# cslr_ddr_001 register map
Vendor: Texas Instruments
Peripheral module from a debugger description file.
Registers are 32-bit, access per field, reset 0x0 unless marked. A register's access mark holds for its fields unless they carry their own. Offsets are as the file gives them; lines under a group give offsets from that group; [hi:lo] are bit positions; {n}, {i} and the like mark numbered series; 'fields as' and 'values as' point back to an identical list; <NAME> marks a mode.

## DDR — External Memory Interface - DDR
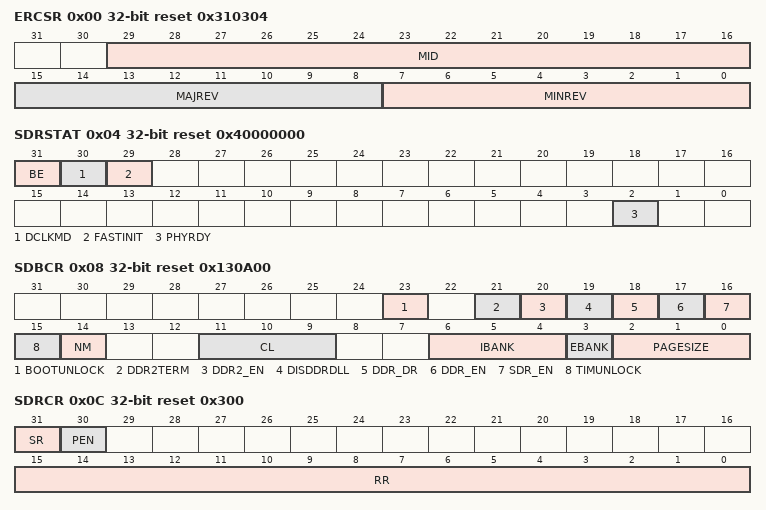
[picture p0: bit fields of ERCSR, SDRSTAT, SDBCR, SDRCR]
0x00 ERCSR ro reset 0x310304 — EMIF Revision Code and Status register
  [29:16] MID — EMIF Module ID
  [15:8] MAJREV — EMIF Major Revision Number
  [7:0] MINREV — EMIF Minor Revision Number
0x04 SDRSTAT ro reset 0x40000000 — SDRAM Status Register
  [31] BE — Big Endian Specifies whether the EMIF is in big or little endian mode
  [30] DCLKMD — Dual Clock Mode Specifies whether the vclk and mclk inputs are asynchronous
  [29] FASTINIT — Fast Init Specifies whether EMIF fast initialization mode has been enabled
  [2] PHYRDY — DDR PHY Ready Specifies whether the DDR PHY is ready for normal operation
0x08 SDBCR reset 0x130A00 (reset mask 0xFF9BFF8F) — SDRAM Bank Configuration Register
  [23] BOOTUNLOCK rw — Boot Unlock Set to 1 to change values of register fields that are affected by this bit.
  [21] DDR2TERM rw — DDR2 Termination resistor value. Set to 1 for 150 ohm, 0 for 75 ohm
    0=TERM75 (Termination resistor = 75 ohm); 1=TERM150 (Termination resistor = 150 ohm)
  [20] DDR2_EN rw — DDR2 Enable Specifies whether the DDR2 mode has been enabled
  [19] DISDDRDLL rw — Disable DLL select for DDR1 SDRAM Set to 1 to disable DLL inside DDR1 SDRAM
  [18] DDR_DR rw — DDR SDRAM drive strength.
    0=NORM (Normal drive strength); 1=WEAK (Weak drive strength)
  [17] DDR_EN rw — Double Rate Specifies whether the EMIF is set to operate at double or single data rate
  [16] SDR_EN rw — SDRAM Enable. Define whether the SDRAM mode of the EMIF is enabled.
  [15] TIMUNLOCK rw — Timing unlock.
    1=UNLOCKTIM (Allowed to change values affected by this field)
  [14] NM rw — SDRAM Data Bus Width Set to 1 when the system bus width to memory bus width is 2:1 for SDR SDRAM and 4:1 for DDR SDRAM A write to this field will cause the EMIF to start the SDRAM initialization sequence
  [11:9] CL rw — CAS Latency A write to this field will cause the EMIF to start the SDRAM initialization sequence
    {v}=CASLAT{v} (CAS Latency of {v}) (v=2..5)
  [6:4] IBANK rw — Internal SDRAM Bank Setup Defines the number of banks inside the SDRAM connected
    0=SD1BANK (1 Bank SDRAM devices); 1=SD2BANK (2 Bank SDRAM devices); 2=SD4BANK (4 Bank SDRAM devices); 3=SD8BANK (8 Bank SDRAM devices)
  [3] EBANK rw — External SDRAM Bank Setup Defines whether the SDRAM bank accesses will use 1 or 2 chip select lines. A write to this field will cause the EMIF to start the SDRAM initialization sequence
    0=CS0 (CS0 is used for SDRAM accesses); 1=CS0_CS1 (CS0 and CS1 are used for SDRAM accesses)
  [2:0] PAGESIZE rw — Page Size Defines the internal page size of the connected SDRAM devices
    0=P256 (256-word pages requiring A[7:0] address pins); 1=P512 (512-word pages requiring A[8:0] address pins); 2=P1024 (1024-word pages requiring A[9:0] address pins); 3=P2048 (2048-word pages requiring A[10:0] address pins)
0x0C SDRCR reset 0x300 — SDRAM Refresh Control Register
  [31] SR rw — Self Refresh Writing a 1 to this bit will cause connected SDRAM devices to be placed into Self Refresh power-down mode and the EMIF to enter the Self-Refresh state
    1=SELFREF (Enter self refresh mode)
  [30] PEN rw — Error Detection 0: Disable error detection 1: Enable error detection
    0=DISABLE (Disable error detection); 1=ENABLE (Enable error detection)
  [15:0] RR rw — Refresh Rate Defines the rate at which EMIF refreshes the connected SDRAM devices. The refresh rate is the number of clock cycles required to cause a refresh interval for the appropriate SDRAM used SDRAM refresh rate = EMIF rate/ refresh rate where EMIF rate is equal to mclk rate Writing a value and#60; 0x0010 to this field will cause it to be loaded with the refresh_def_value
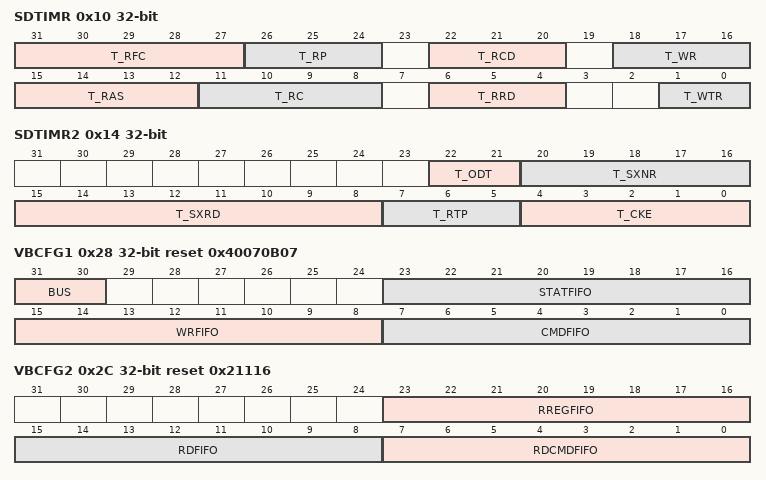
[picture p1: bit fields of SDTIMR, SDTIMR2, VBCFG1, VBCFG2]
0x10 SDTIMR — SDRAM Timing Register
  [31:27] T_RFC rw — Specifies Trfc value of the SDRAM is minimum number of EMIF clock cycles from Refresh (REFR) or Load Mode (MRS) to Refresh (REFR) or Activate (ACTV) command, minus one TRFC = (Trfc / SDCLK) - 1
  [26:24] T_RP rw — Specifies Trp value of the SDRAM is minimum number of EMIF cycles from Pre-charge to Active (ACTV) or Refresh (REFR/), minus one TRP = (Trp / SDCLK) - 1
  [22:20] T_RCD rw — Specifies Trcd value of the SDRAM is minimum number of EMIF cycles from Active (ACTV) to read (READ) or write (WRITE) command, minus one TRCD = (Trcd / SDCLK) - 1
  [18:16] T_WR rw — Specifies Twr value of the SDRAM is minimum number of EMIF cycles from last write transfer to Precharge command, minus one TWR = (Twr / SDCLK) - 1
  [15:12] T_RAS rw — Specifies Tras value of the SDRAM in EMIF clock cycles from Activate (ACT) to Precharge command, minus one TRAS = (Tras / SDCLK) - 1
  [11:8] T_RC rw — Specifies Trc value of the SDRAM is minimum number of EMIF clock cycles from Activate (ACT) to Activate (ACT) command, minus one TRC = (Trc / SDCLK) - 1
  [6:4] T_RRD rw — Specifies Trrd value of the SDRAM is minimum number of EMIF clock cycles from Activate (ACT) to Activate (ACT) command for a different bank, minus one TRRD = (Trrd / SDCLK) - 1
  [1:0] T_WTR rw — Specifies the minimum number of EMIF clock cycles from the last DDR write transfer to DDR read, minus one
0x14 SDTIMR2 — SDRAM Timing Register 2
  [22:21] T_ODT rw — Specified the minimum number of EMIF cycles minus one from ODT enable to write data driven. This field must be equal to (CAS latency -tAOND-1)
  [20:16] T_SXNR rw — Specifies the minimum number of EMIF clock cycles minus one from self-fresh exit to any command (except READ).
  [15:8] T_SXRD rw — Specifies the minimum number of EMIF clock cycles minus one from self-fresh exit to READ command.
  [7:5] T_RTP rw — Specifies the minimum number of EMIF clock cycles minus one from the last READ command to a Pre-Charge command.
  [4:0] T_CKE rw — Specifies the minimum number of EMIF clock cycles minus one for the pulse width of pad_mcke_o. This signal is used to put SDRAM devices in Self Refresh of Power Down.
0x20 VBPR reset 0xFF — VBUSM Burst Priority Register
  [7:0] PROC rw — Priority Raise Old Counter Specifies the number of memory bursts after which the EMIF raises the priority of old commands in the VBUSM Command FIFO
0x28 VBCFG1 ro reset 0x40070B07 — VBUSM Config Value 1 Register
  [31:30] BUS — VBUSM data bus width. 0:32-bit 1:64-bit 2 and 3: Reserved
  [23:16] STATFIFO — Write status FIFO depth.
  [15:8] WRFIFO — Write FIFO depth
  [7:0] CMDFIFO — Command FIFO depth.
0x2C VBCFG2 ro reset 0x21116 — VBUSM Config Value 2 Register
  [23:16] RREGFIFO — Async/Register read FIFO depth.
  [15:8] RDFIFO — SDRAM read FIFO depth.
  [7:0] RDCMDFIFO — Read command FIFO depth.
0x40 PERFC1R ro — Performance Counter 1 Register
  [31:0] COUNTER1 — 32-bit counter that can be configured as specified in the Performance Counter Config Register and Performance Counter Master Region Select Register This register is used for performance monitoring and is cleared only on reset
0x44 PERFC2R ro — Performance Counter 2 Register
  [31:0] COUNTER2 — 32-bit counter that can be configured as specified in the Performance Counter Config Register and Performance Counter Master Region Select Register This register is used for performance monitoring and is cleared only on reset
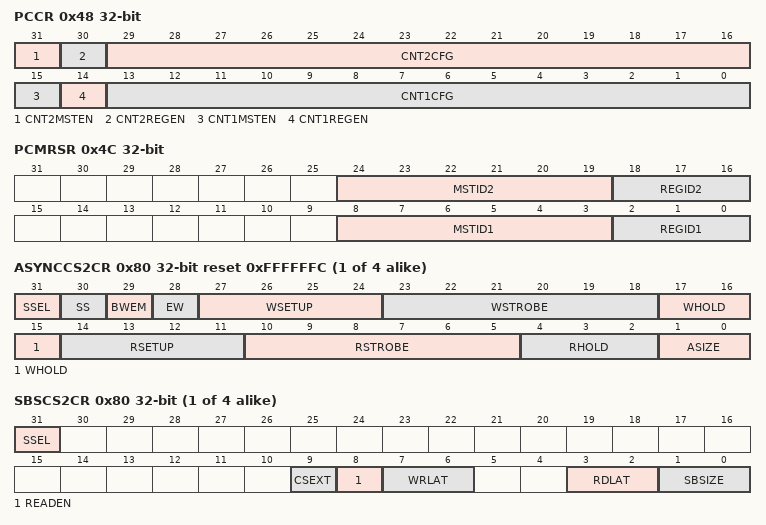
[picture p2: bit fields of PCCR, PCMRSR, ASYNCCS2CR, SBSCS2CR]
0x48 PCCR rw — Performance Counter Config Register
  [31] CNT2MSTEN — Master ID filter enable for Performance Counter 2
  [30] CNT2REGEN — Chip Select filter enable for Performance Counter 2
  [29:16] CNT2CFG — Filter configuration for Performance Counter 2
    0=SDACC (Total SDRAM accesses.); 1=SDACT (Total SDRAM activates.); 2=TOTRD (Total reads.); 3=TOTWR (Total writes.); 4=COMFULL (Number of cycles VBUSM command fifo is full.); 5=WRDATFULL (Number of cycles VBUSM write data fifo is full.); 6=RDDATFULL (Number of cycles VBUSM read data fifo is full.); 7=WRSTATFULL (Number of cycles VBUSM write status fifo is full.); 8=TOTPARERR (Total parity errors.); 9=PRIELEV (Number of priority elevations.); 10=PCHRGELEV (Number of pre-charge elevations.); 11=CMDPND (Number of cycles that a command was pending.)
  [15] CNT1MSTEN — Master ID filter enable for Performance Counter 1
  [14] CNT1REGEN — Chip Select filter enable for Performance Counter 1
  [13:0] CNT1CFG — Filter configuration for Performance Counter 1
    values as CNT2CFG
0x4C PCMRSR — Performance Counter Master Region Select Register
  [24:19] MSTID2 rw — Master ID for Performance Counter 2
  [18:16] REGID2 rw — Chip Select for Performance Counter 2
  [8:3] MSTID1 rw — Master ID for Performance Counter 1
  [2:0] REGID1 rw — Chip Select for Performance Counter 1
{0x78+4i} ASYNCCS{i}CR rw reset 0xFFFFFFC (i=2..5) — CS{i} Config Register for Asynchronous Memory Access (ssel = 0)
  [31] SSEL — Sync SBSRAM/Asynchronous memory select Set to 1 to configure chip select for synchronous SBSRAM memory. The other fields in this register define the bits in the bank when SSEL is set to 0 (asynchronous memory mode)
  [30] SS — Select Strobe mode Set to 1 if chip selects need to have write or read strobe timing
  [29] BWEM — Select WE Strobe mode When set to 1, the pado_mdqm_o_n[7/3:0] output pins will act as active low byte enables when accessing chip select N
  [28] EW — Extend Wait mode Set to 1 if extended asynchronous cycles are required based on padi_mwait_I
  [27:24] WSETUP — Wait Strobe Setup cycles Number of EMIF clock cycles from pado_ma_o, pado_mba_o, pad_d_o, pado_mdqm_o_n, and pado_mcs_o_n being set to pado_mwe_o_n asserted,minus one cycle.The reset value is 16 cycles
  [23:18] WSTROBE — Wait Strobe Duration cycles Number of EMIF clock cycles for which pado_mwe_o_n is held active, minus one cycle
  [17:15] WHOLD — Wait Strobe Hold cycles Number of EMIF clock cycles for which pado_ma_o, pado_mba_o, pad_d_o, pado_mdqm_o_n, and pado_mcs_o_n are held after pado_mwe_o_n has been deasserted, minus one cycle. The reset value is 8 cycles
  [14:11] RSETUP — Read Strobe Setup cycles Number of EMIF clock cycles from pado_ma_o, pado_mba_o, pado_mdqm_o_n, and pado_mcs_o_n being set to pado_moe_o_n asserted, minus one cycle. The reset value is 16 cycles
  [10:5] RSTROBE — Read Strobe Duration cycles Number of EMIF clock cycles for which pado_moe_o_n is held active, minus one cycle. The reset value is 64 cycles
  [4:2] RHOLD — Read Strobe Hold cycles Number of EMIF clock cycles for which pado_ma_o, pado_mba_o, pado_mdqm_o_n, and pado_mcs_o_n are held after pado_moe_o_n has been deasserted, minus one cycle. The reset value is 8 cycles
  [1:0] ASIZE — Asynchronous Bank Size Defines the width of the asynchronous bank's data bus, as follows
    0=DATA8 (8-bit data bus); 1=DATA16 (16-bit data bus); 2=DATA32 (32-bit data bus); 3=DATA64 (64-bit data bus)
{0x78+4i} SBSCS{i}CR (i=2..5) — CS{i} Config Register for Synchronous Burst SRAM Access (ssel = 1)
  [31] SSEL rw — Sync SBSRAM/Asynchronous memory select Set to 1 to configure chip select for synchronous SBSRAM memory. The other fields in this register define the bits in the bank when SSEL is set to 0 (asynchronous memory mode)
  [9] CSEXT rw — SBSRAM Bank Chip Select Extend. Defines the behavior of the pad_cs_o[n] pin associated with the SBSRAM bank, as follows 0: pad_cs_o[n] goes inactive after final command has been issued 1: pad_cs_o[n] goes active low when pado_moe_o_n goes active low and will stay active low until pado_moe_o_n is inactive.The pado_moe_o_n tining is controlled by the r_ltncy value for the SBSRAM bank. Used for synchronous FIFO reads
  [8] READEN rw — SBSRAM Bank Read Enable Mode Defines the behavior of the pado_mads_o_n signal when accessing the SBSRAM bank, as follows: 0: ADS mode.The pado_mads_o_n signal goes active low for reads and writes. A deselect command is issued by driving pado_mads_o_n active high after a command, if no new command is pending for the same bank. Used for SBSRAM and ZBT devices 1: Read enable mode. The pado_mads_o_n signal goes active low only for reads. No deselect command is issued. Used for FIFO interfaces
  [7:6] WRLAT rw — SBSRAM Bank Write Latency Defines the SBSRAM bank's write latency in clock cycles
    {v}={v} Cycle Write Latency (v=0..3)
  [3:2] RDLAT rw — SBSRAM Bank Read Latency Defines the SBSRAM bank's read latency in clock cycles, as follows:
    {v}={v} Cycle Read Latency (v=0..3)
  [1:0] SBSIZE rw — SBSRAM Bank Size Defines width of the SBSRAM bank's data bus
    values as ASYNCCS2CR.ASIZE
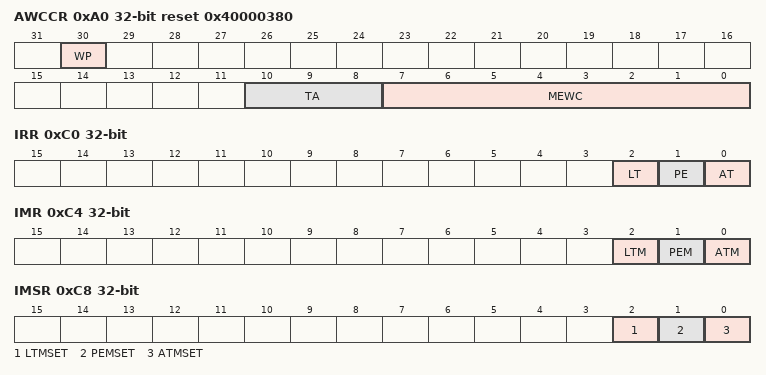
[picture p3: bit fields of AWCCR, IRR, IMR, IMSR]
0xA0 AWCCR reset 0x40000380 — Async Wait Cycle Config Register
  [30] WP rw — Wait Polarity Defines the polarity of the padpadi_mwait_i port, as follows: 0: Wait if padpadi_mwait_i port is low 1: Wait if padpadi_mwait_i port is high
  [10:8] TA rw — Turn Around cycles Number of EMIF clock cycles between the end of one asynchronous bank access and the start of another asynchronous bank access, minus one cycle. This delay is not incurred between a read followed by a read, or a write followed by a write to the same bank. The reset value is 4 cycles
  [7:0] MEWC rw — Maximum External Wait cycles The value in this field defines the number of 16 EMIF cycle periods the EMIF will wait for an extended asynchronous cycle before the cycle is terminated
0xC0 IRR — Interrupt Raw Register
  [2] LT rw — Line Trap Set to 1 by hardware to indicate illegal memory access type or invalid cache line size. Writing a 1 will clear this bit as well as the lt_masked bit in the Interrupt Masked register. Writing a 0 has no effect
  [1] PE rw — Parity Error Set to 1 by hardware to indicate a parity error during SDRAM access. Writing a 1 will clear this bit as well as the pe_masked bit in the Interrupt Masked register. Writing a 0 has no effect
  [0] AT rw — Asynchronous Timeout Set to 1 by hardware to indicate that during an extended asynchronous bank access cycle, the padi_mwait_i signal did not go inactive within the number of cycles defined by the max_ext_wait field in Async Wait Cycle Config register. Writing a 1 will clear this bit as well as the at_masked bit in the Interrupt Masked register. Writing a 0 has no effect
0xC4 IMR — Interrupt Masked Register
  [2] LTM rw — Masked Line Trap Set to 1 by hardware to indicate illegal memory access type or invalid cache line size. Writing a 1 will clear this bit as well as the lt bit in the Interrupt Raw register. Writing a 0 has no effect
  [1] PEM rw — Masked Parity Error Set to 1 by hardware to indicate a parity error during SDRAM access. Writing a 1 will clear this bit as well as the pe bit in the Interrupt Raw register. Writing a 0 has no effect
  [0] ATM rw — Masked Asynchronous Timeout Set to 1 by hardware to indicate that during an extended asynchronous bank access cycle, the padi_mwait_i signal did not go inactive within the number of cycles defined by the max_ext_wait field in Async Wait Cycle Config register. Writing a 1 will clear this bit as well as the at bit in the Interrupt Raw register. Writing a 0 has no effect
0xC8 IMSR — Interrupt Mask Set Register
  [2] LTMSET rw — Line Trap Mask Set Bit Writing a 1 in this bit field will enable the interrupt and set this bit in the Line Trap Mask bit field of the Interrupt Mask Clear Register. This bit is cleared by writing a 1 into this bit field
  [1] PEMSET rw — Parity Error Mask Set Bit Writing a 1 will enable the interrupt, and set this bit as well as the pe_mask_clr bit in the Interrupt Mask Clear register. Writing a 0 has no effect
  [0] ATMSET rw — Asynchronous Timeout Mask Set Bit Writing a 1 in this bit field will enable the interrupt and set this bit in the Asynchronous Timeout Mask Clear bit field of the Interrupt Mask Register. This bit is cleared by writing a 1 into this bit field
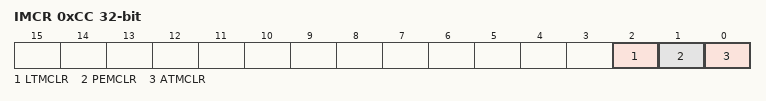
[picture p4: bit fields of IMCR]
0xCC IMCR — Interrupt Mask Clear Register
  [2] LTMCLR rw — Line Trap Mask Clear Bit Writing a 1 in this bit field will disable the interrupt and clear this bit in the Line Trap Mask Set bit field of the Interrupt Mask Register. This bit is cleared by writing a 1 into this bit field. Writing a 0 has no effect.
  [1] PEMCLR rw — Parity Error Mask Clear Bit Writing a 1 will disable the interrupt, and clear this bit as well as the pe_mask_set bit in the Interrupt Mask Set register. Writing a 0 has no effect
  [0] ATMCLR rw — Asynchronous Timeout Mask Clear Bit Writing a 1 in this bit field will disable the interrupt and clear this bit in the Asynchronous Timeout Mask Set bit field of the Interrupt Mask Register. This bit is cleared by writing a 1 into this bit field. Writing a 0 has no effect
0xE0 DDRPHYREV rw — DDR PHY ID and Revision Register
  [31:0] DDRPHYIDREV — This register specifies the module ID and revision of the DDR PHY being used The bit field definitions are DDR PHY specific and should be described in the DDR PHY specification
0xE4 DDRPHYCR rw — DDR PHY Control Register
  [31:0] DDRPHYCTRL — This register is used to control the DDR PHY The bit field definitions are DDR PHY specific and should be described in the DDR PHY specifications
0xE8 DDRPHYSR ro — DDR PHY Status Register
  [31:0] DDRPHYSTAT — This register is used to monitor the status of the DDR PHY The bit field definitions are DDR PHY specific and should be described in the DDR PHY specifications
0xF0 VTPCTRL — DDR PHY Status Register
  [15:0] IOCTRL rw — This register is used to control the IOs such as the VTP calibration of the IOs.
0xF4 VTPSTAT — DDR PHY Status Register
  [3:0] IOCTRL rw — This register is used to monitor the status of the IOs such as the VTP calibration of the IOs.
